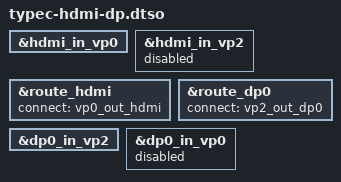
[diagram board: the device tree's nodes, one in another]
/dts-v1/;
/plugin/;

/* ==========  HDMI in VP0 ========== */

&hdmi_in_vp0 {
	status = "okay";
};

&hdmi_in_vp2 {
	status = "disabled";
};

&route_hdmi {
	status = "okay";
	connect = <&vp0_out_hdmi>;
};

&route_dp0 {
	status = "okay";
	connect = <&vp2_out_dp0>;
};

/* ========== Display Path: VP2 → DP0 ========== */

/* Enable VP2 → DP0 path */
&dp0_in_vp2 {
	status = "okay";
};

/* Disable VP0 → DP0 */
&dp0_in_vp0 {
	status = "disabled";
};
